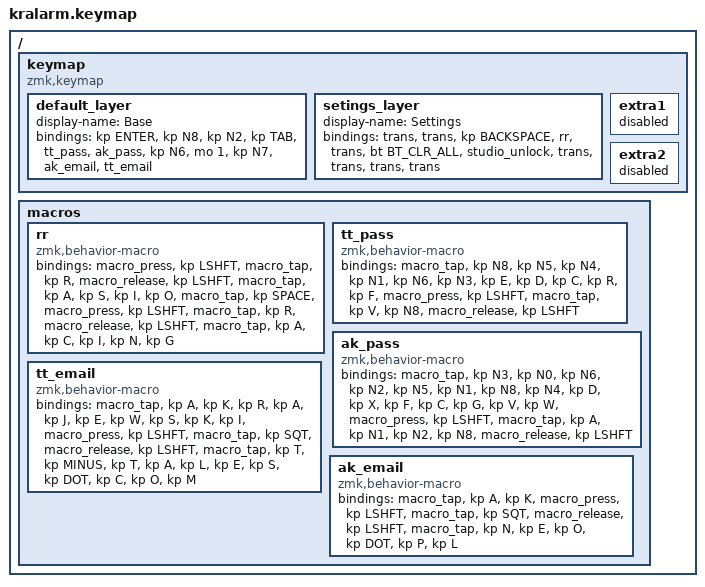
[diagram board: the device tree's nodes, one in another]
#include <behaviors.dtsi>
#include <dt-bindings/zmk/keys.h>
#include <dt-bindings/zmk/bt.h>

/ {
    keymap {
        compatible = "zmk,keymap";
        default_layer {
            display-name = "Base";
            bindings = <
            &kp ENTER //RIGHT_ARROW     //0
            &kp N8 //RIGHT_ARROW     //1
            &kp N2 //RIGHT_ARROW     //2
            &kp TAB //DOWN_ARROW      //3
            &tt_pass //LEFT_ARROW      //4
            &ak_pass //UP_ARROW        //5
            &kp N6 //ENTER           //6
            &mo 1                    //7
            &kp N7 //LEFT_ARROW      //8
            &ak_email //LEFT_ARROW      //9
            &tt_email //LEFT_ARROW      //10
            >;
        };
        setings_layer {
            display-name = "Settings";
            bindings = <
            &trans              //0
            &trans              //1
            &kp BACKSPACE       //2
            &rr                 //3
            &trans              //4
            &bt BT_CLR_ALL      //5
            &studio_unlock      //6
            &trans              //7
            &trans              //8
            &trans              //9
            &trans              //10
            >;
        };
        extra1 {
            status = "reserved";
        };

        extra2 {
            status = "reserved";
        };
    };
};
/ {
    macros {
        rr: rr {
            compatible = "zmk,behavior-macro";
            #binding-cells = <0>;
            bindings
                = <&macro_press &kp LSHFT>
                , <&macro_tap &kp R>
                , <&macro_release &kp LSHFT>
                , <&macro_tap &kp A &kp S &kp I &kp O>
                , <&macro_tap &kp SPACE>
                , <&macro_press &kp LSHFT>
                , <&macro_tap &kp R>
                , <&macro_release &kp LSHFT>
                , <&macro_tap &kp A &kp C &kp I &kp N &kp G>
                ;
        };
        tt_pass: tt_pass {
            compatible = "zmk,behavior-macro";
            #binding-cells = <0>;
            bindings
                = <&macro_tap &kp N8 &kp N5 &kp N4 &kp N1 &kp N6 &kp N3 &kp E &kp D &kp C &kp R &kp F>
                , <&macro_press &kp LSHFT>
                , <&macro_tap &kp V &kp N8>
                , <&macro_release &kp LSHFT>
                ;
        };
        ak_pass: ak_pass {
            compatible = "zmk,behavior-macro";
            #binding-cells = <0>;
            bindings
                = <&macro_tap &kp N3 &kp N0 &kp N6 &kp N2 &kp N5 &kp N1 &kp N8 &kp N4 &kp D &kp X &kp F &kp C &kp G &kp V &kp W>
                , <&macro_press &kp LSHFT>
                , <&macro_tap &kp A &kp N1 &kp N2 &kp N8>
                , <&macro_release &kp LSHFT>
                ;
        };
        tt_email: tt_email {
            compatible = "zmk,behavior-macro";
            #binding-cells = <0>;
            bindings
                = <&macro_tap &kp A &kp K &kp R &kp A &kp J &kp E &kp W &kp S &kp K &kp I>
                , <&macro_press &kp LSHFT>
                , <&macro_tap &kp SQT>
                , <&macro_release &kp LSHFT>                
                , <&macro_tap &kp T &kp MINUS &kp T &kp A &kp L &kp E &kp S &kp DOT &kp C &kp O &kp M>
                ;
        };
        ak_email: ak_email {
            compatible = "zmk,behavior-macro";
            #binding-cells = <0>;
            bindings
                = <&macro_tap &kp A &kp K>
                , <&macro_press &kp LSHFT>
                , <&macro_tap &kp SQT>
                , <&macro_release &kp LSHFT>                
                , <&macro_tap &kp N &kp E &kp O &kp DOT &kp P &kp L>
                ;
        };
    };
};
